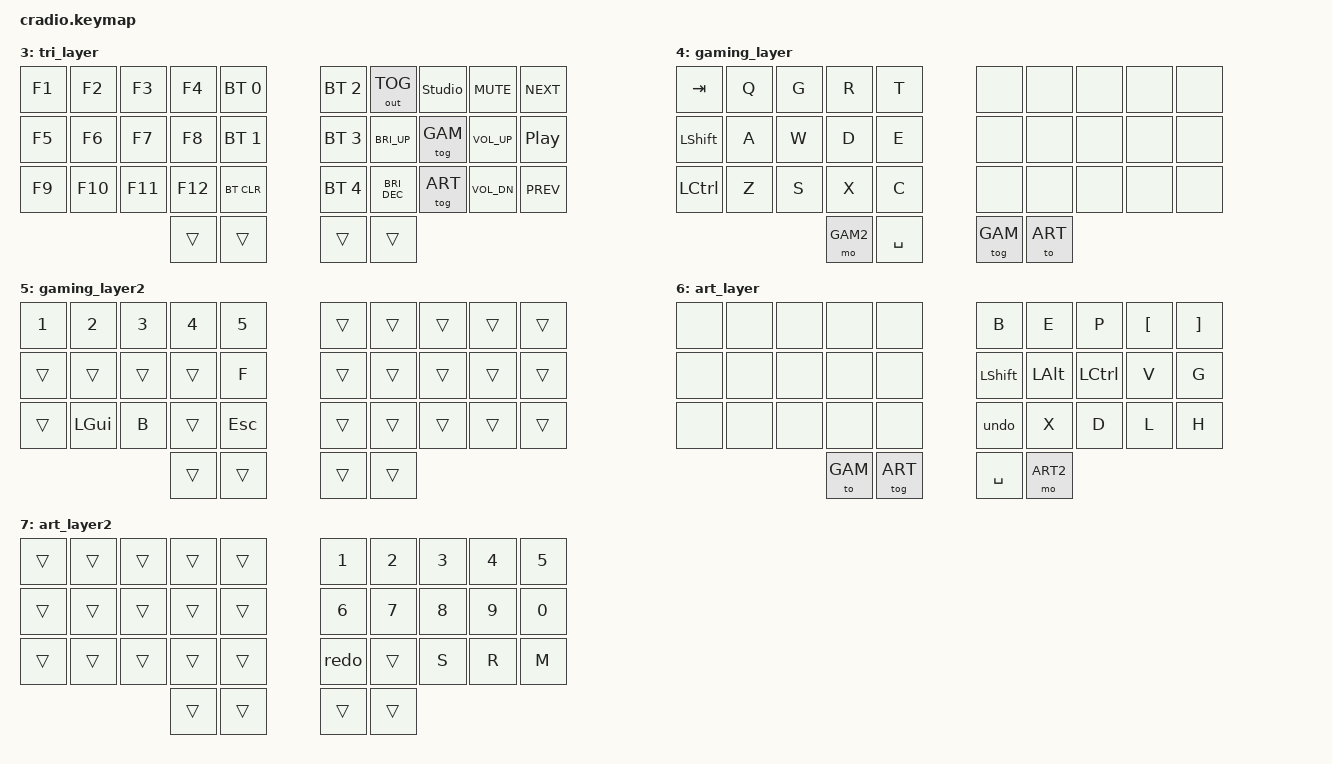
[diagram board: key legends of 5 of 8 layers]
// Copyright (c) 2022 The ZMK Contributors
// SPDX-License-Identifier: MIT

#include <behaviors.dtsi>
#include <dt-bindings/zmk/keys.h>
#include <dt-bindings/zmk/bt.h>
#include <dt-bindings/zmk/outputs.h>

#define DEF 0
#define RIG 1
#define LEF 2
#define TRI 3
#define GAM 4
#define GAM2 5
#define ART 6
#define ART2 7

// Key positions for positional hold-tap
// ╭─────────────────────╮   ╭─────────────────────╮
// │  0   1   2   3   4  │   │  5   6   7   8   9  │
// │ 10  11  12  13  14  │   │ 15  16  17  18  19  │
// │ 20  21  22  23  24  │   │ 25  26  27  28  29  │
// ╰───────────╮ 30  31  │   │ 32  33 ╭────────────╯
//             ╰─────────╯   ╰────────╯
#define KEYS_L 0 1 2 3 4 10 11 12 13 14 20 21 22 23 24
#define KEYS_R 5 6 7 8 9 15 16 17 18 19 25 26 27 28 29
#define THUMBS 30 31 32 33

// Home row mods macros
#define HRML(k1,k2,k3,k4) &hml LALT k1  &hml LCTRL k2  &hml LSHFT k3  &hml LGUI k4
#define HRMR(k1,k2,k3,k4) &hmr LGUI k1  &hmr LSHFT k2  &hmr LCTRL k3  &hmr LALT k4

/ {
    behaviors {
        hml: home_row_mod_left {
            compatible = "zmk,behavior-hold-tap";
            #binding-cells = <2>;
            flavor = "balanced";
            tapping-term-ms = <280>;
            quick-tap-ms = <175>;
            require-prior-idle-ms = <150>;
            bindings = <&kp>, <&kp>;
            hold-trigger-key-positions = <KEYS_R THUMBS>;
            hold-trigger-on-release;
        };

        hmr: home_row_mod_right {
            compatible = "zmk,behavior-hold-tap";
            #binding-cells = <2>;
            flavor = "balanced";
            tapping-term-ms = <280>;
            quick-tap-ms = <175>;
            require-prior-idle-ms = <150>;
            bindings = <&kp>, <&kp>;
            hold-trigger-key-positions = <KEYS_L THUMBS>;
            hold-trigger-on-release;
        };
    };

    macros {
        undo: undo {
            compatible = "zmk,behavior-macro";
            #binding-cells = <0>;
            bindings = <&macro_press &kp LCTRL>, <&macro_tap &kp Z>, <&macro_release &kp LCTRL>;
        };
        redo: redo {
            compatible = "zmk,behavior-macro";
            #binding-cells = <0>;
            bindings = <&macro_press &kp LCTRL &kp LSHFT>, <&macro_tap &kp Z>, <&macro_release &kp LSHFT &kp LCTRL>;
        };

        // Romanian diacritics (AltGr + key, for Romanian Programmers layout)
        ro_a_breve: ro_a_breve {  // Ă
            compatible = "zmk,behavior-macro";
            #binding-cells = <0>;
            bindings = <&macro_press &kp RALT>, <&macro_tap &kp A>, <&macro_release &kp RALT>;
        };
        ro_a_circ: ro_a_circ {  // Â
            compatible = "zmk,behavior-macro";
            #binding-cells = <0>;
            bindings = <&macro_press &kp RALT>, <&macro_tap &kp Q>, <&macro_release &kp RALT>;
        };
        ro_i_circ: ro_i_circ {  // Î
            compatible = "zmk,behavior-macro";
            #binding-cells = <0>;
            bindings = <&macro_press &kp RALT>, <&macro_tap &kp I>, <&macro_release &kp RALT>;
        };
        ro_s_comma: ro_s_comma {  // Ș
            compatible = "zmk,behavior-macro";
            #binding-cells = <0>;
            bindings = <&macro_press &kp RALT>, <&macro_tap &kp S>, <&macro_release &kp RALT>;
        };
        ro_t_comma: ro_t_comma {  // Ț
            compatible = "zmk,behavior-macro";
            #binding-cells = <0>;
            bindings = <&macro_press &kp RALT>, <&macro_tap &kp T>, <&macro_release &kp RALT>;
        };
    };

    conditional_layers {
        compatible = "zmk,conditional-layers";
        tri_layer {
            if-layers = <RIG LEF>;
            then-layer = <TRI>;
        };
    };

    keymap {
        compatible = "zmk,keymap";
        default_layer {
            bindings = <
        //╭──────────┬──────────┬──────────┬──────────┬──────────╮   ╭──────────┬──────────┬──────────┬──────────┬──────────╮
        //│  Q       │  W       │  E       │  R       │  T       │   │  Y       │  U       │  I       │  O       │  P       │
            &kp Q      &kp W      &kp E      &kp R      &kp T          &kp Y      &kp U      &kp I      &kp O      &kp P
        //├──────────┼──────────┼──────────┼──────────┼──────────┤   ├──────────┼──────────┼──────────┼──────────┼──────────┤
        //│  A       │  S/ALT   │  D/CTRL  │  F/SHIFT │  G/GUI   │   │  H/GUI   │  J/SHIFT │  K/CTRL  │  L/ALT   │BACKSPACE │
            &kp A      HRML(S,        D,         F,         G)         HRMR(H,        J,         K,         L)     &kp BSPC
        //├──────────┼──────────┼──────────┼──────────┼──────────┤   ├──────────┼──────────┼──────────┼──────────┼──────────┤
        //│  Z       │  X       │  C       │  V       │  B       │   │  N       │  M       │ , <      │ . >      │ ENTER    │
            &kp Z      &kp X      &kp C      &kp V      &kp B          &kp N      &kp M      &kp COMMA  &kp DOT    &kp ENTER
        //╰──────────┴──────────┴──────────┼──────────┼──────────┤   ├──────────┼──────────┼──────────┴──────────┴──────────╯
                                          &lt LEF TAB  &kp SPACE     &kp SPACE  &lt RIG TAB
        //                                 ╰──────────┴──────────╯   ╰──────────┴──────────╯
            >;
        };

        right_layer {
            bindings = <
        //╭──────────┬──────────┬──────────┬──────────┬──────────╮   ╭──────────┬──────────┬──────────┬──────────┬──────────╮
        //│ 1        │  2       │  3       │  4       │  5       │   │ 6        │ 7        │ 8        │ 9        │   0      │
            &kp N1    &kp N2     &kp N3     &kp N4     &kp N5          &kp N6     &kp N7     &kp N8     &kp N9      &kp N0
        //├──────────┼──────────┼──────────┼──────────┼──────────┤   ├──────────┼──────────┼──────────┼──────────┼──────────┤
        //│  Ă       │  Â       │  Î       │  Ș       │  Ț       |   |HOME/GUI  │PGDN/SHFT │PGUP/CTRL │ END/ALT  │          │
          &ro_a_breve &ro_a_circ &ro_i_circ &ro_s_comma &ro_t_comma  HRMR(HOME,     PG_DN,     PG_UP,     END)      &trans
        //├──────────┼──────────┼──────────┼──────────┼──────────┤   ├──────────┼──────────┼──────────┼──────────┼──────────┤
        //│ DELETE   │ CapsLock │ PrintSc  │  INSERT  │ ESCAPE   │   │ LEFT     │ DOWN     │ UP       │ RIGHT    │          │
            &kp DEL   &kp CAPS   &kp PSCRN  &kp INS    &kp ESC        &kp LARW   &kp DARW   &kp UARW   &kp RARW    &trans
        //╰──────────┴──────────┴──────────┼──────────┼──────────┤   ├──────────┼──────────┼──────────┴──────────┴──────────╯
                                             &trans     &trans         &trans     &trans
        //                                 ╰──────────┴──────────╯   ╰──────────┴──────────╯
            >;
        };

        left_layer {
            bindings = <
        //╭──────────┬──────────┬──────────┬──────────┬──────────╮   ╭──────────┬──────────┬──────────┬──────────┬──────────╮
        //│  !       │  @       │  #       │  $       │  %       │   │  ^       │  &       │  *       │  `       │  ~       │
            &kp EXCL   &kp AT     &kp HASH   &kp DLLR   &kp PRCNT      &kp CARET  &kp AMPS   &kp ASTRK  &kp GRAVE   &kp TILDE
        //├──────────┼──────────┼──────────┼──────────┼──────────┤   ├──────────┼──────────┼──────────┼──────────┼──────────┤
        //│  "       │  [/ALT   │  {/CTRL  │  (/SHIFT │          │   │   //GUI  │  -/SHIFT │  =/CTRL  │  :/ALT   │  ;       │
            &kp DQT  &hml LALT LBKT &hml LCTRL LBRC &hml LSHFT LPAR &trans   HRMR(FSLH,     MINUS,     EQUAL,     COLON)   &kp SEMI
        //├──────────┼──────────┼──────────┼──────────┼──────────┤   ├──────────┼──────────┼──────────┼──────────┼──────────┤
        //│  '       │  ]       │  }       │  )       │          │   │    \     │  _       │  +       │  │       │   ?      │
            &kp SQT     &kp RBKT   &kp RBRC   &kp RPAR   &trans         &kp BSLH   &kp UNDER  &kp PLUS   &kp PIPE  &kp QMARK
        //╰──────────┴──────────┴──────────┼──────────┼──────────┤   ├──────────┼──────────┼──────────┴──────────┴──────────╯
                                             &trans     &trans         &trans     &trans
        //                                 ╰──────────┴──────────╯   ╰──────────┴──────────╯
            >;
        };

        tri_layer {
            bindings = <
        //╭──────────┬──────────┬──────────┬───────────┬────────────╮   ╭────────────┬────────────┬──────────┬───────────┬──────────╮
        //│  F1      │  F2      │  F3      │  F4       │ PROFILE 0  │   │ PROFILE 2  │ TOGGLEOUT  │ STUDIO   │ VOL MUTE  │ NEXTSONG │
            &kp F1     &kp F2     &kp F3     &kp F4     &bt BT_SEL 0     &bt BT_SEL 2  &out OUT_TOG  &studio_unlock  &kp C_MUTE  &kp C_NEXT
        //├──────────┼──────────┼──────────┼───────────┼────────────┤   ├────────────┼────────────┼──────────┼───────────┼──────────┤
        //│  F5      │  F6      │  F7      │  F8       │ PROFILE 1  │   │ PROFILE 3  │ INC BRIGHT │ GAMING   │  VOL UP   │PAUSEMUSIC│
            &kp F5     &kp F6     &kp F7     &kp F8     &bt BT_SEL 1     &bt BT_SEL 3  &kp C_BRI_UP  &tog GAM  &kp C_VOL_UP  &kp C_PP
        //├──────────┼──────────┼──────────┼───────────┼────────────┤   ├────────────┼────────────┼──────────┼───────────┼──────────┤
        //│  F9      │  F10     │  F11     │  F12      │  CLEAR BT  │   │ PROFILE 4  │ DEC BRIGHT │  ART     |  VOL DOWN │ PREVSONG │
            &kp F9     &kp F10    &kp F11    &kp F12     &bt BT_CLR      &bt BT_SEL 4  &kp C_BRI_DEC  &tog ART  &kp C_VOL_DN &kp C_PREV
        //╰──────────┴──────────┴──────────┼───────────┼────────────┤   ├────────────┼────────────┼──────────┴───────────┴──────────╯
                                                &trans     &trans         &trans     &trans
        //                                  ╰───────────┴──────────╯   ╰──────────┴────────────╯
            >;
        };

        gaming_layer {
            bindings = <
        //╭──────────┬──────────┬──────────┬──────────┬──────────╮   ╭──────────┬──────────┬──────────┬──────────┬──────────╮
        //│  TAB     │  Q       │  G       │  R       │  T       │   │          │          │          │          │          │
            &kp TAB    &kp Q      &kp G      &kp R      &kp T          &none      &none      &none      &none      &none
        //├──────────┼──────────┼──────────┼──────────┼──────────┤   ├──────────┼──────────┼──────────┼──────────┼──────────┤
        //│  LSHIFT  │  A       │  W       │  D       │  E       │   │          │          │          │          │          │
            &kp LSHFT  &kp A      &kp W      &kp D      &kp E          &none      &none      &none      &none      &none
        //├──────────┼──────────┼──────────┼──────────┼──────────┤   ├──────────┼──────────┼──────────┼──────────┼──────────┤
        //│  LCTRL   │  Z       │  S       │  X       │  C       │   │          │          │          │          │          │
            &kp LCTRL  &kp Z      &kp S      &kp X      &kp C          &none      &none      &none      &none      &none
        //╰──────────┴──────────┴──────────┼──────────┼──────────┤   ├──────────┼──────────┼──────────┴──────────┴──────────╯
                                            &mo GAM2    &kp SPACE     &tog GAM   &to ART
        //                                 ╰──────────┴──────────╯   ╰──────────┴──────────╯
            >;
        };

        gaming_layer2 {
            bindings = <
        //╭──────────┬──────────┬──────────┬──────────┬──────────╮   ╭──────────┬──────────┬──────────┬──────────┬──────────╮
        //│  1       │  2       │  3       │  4       │  5       │   │          │          │          │          │          │
            &kp N1     &kp N2     &kp N3     &kp N4     &kp N5         &trans     &trans     &trans     &trans     &trans
        //├──────────┼──────────┼──────────┼──────────┼──────────┤   ├──────────┼──────────┼──────────┼──────────┼──────────┤
        //│  ^       │  ^       │  ^       │  ^       │  F       │   │          │          │          │          │          │
            &trans     &trans     &trans     &trans     &kp F          &trans     &trans     &trans     &trans     &trans
        //├──────────┼──────────┼──────────┼──────────┼──────────┤   ├──────────┼──────────┼──────────┼──────────┼──────────┤
        //│  ^       │  GUI     │  B       │  ^       │  ESC     │   │          │          │          │          │          │
            &trans     &kp LGUI   &kp B      &trans     &kp ESC        &trans     &trans     &trans     &trans     &trans
        //╰──────────┴──────────┴──────────┼──────────┼──────────┤   ├──────────┼──────────┼──────────┴──────────┴──────────╯
                                             &trans     &trans         &trans     &trans
        //                                 ╰──────────┴──────────╯   ╰──────────┴──────────╯
            >;
        };

        art_layer {
            bindings = <
        //╭──────────┬──────────┬──────────┬──────────┬──────────╮   ╭──────────┬──────────┬──────────┬──────────┬──────────╮
        //│          │          │          │          │          │   │  B       │  E       │  P       │  [       │  ]       │
            &none      &none      &none      &none      &none          &kp B      &kp E      &kp P      &kp LBKT   &kp RBKT
        //├──────────┼──────────┼──────────┼──────────┼──────────┤   ├──────────┼──────────┼──────────┼──────────┼──────────┤
        //│          │          │          │          │          │   │  LSHIFT  │  LALT    │  LCTRL   │  V       │  G       │
            &none      &none      &none      &none      &none          &kp LSHFT  &kp LALT   &kp LCTRL  &kp V      &kp G
        //├──────────┼──────────┼──────────┼──────────┼──────────┤   ├──────────┼──────────┼──────────┼──────────┼──────────┤
        //│          │          │          │          │          │   │  UNDO    │  X       │  D       │  L       │  H       │
            &none      &none      &none      &none      &none          &undo      &kp X      &kp D      &kp L      &kp H
        //╰──────────┴──────────┴──────────┼──────────┼──────────┤   ├──────────┼──────────┼──────────┴──────────┴──────────╯
                                             &to GAM    &tog ART      &kp SPACE  &mo ART2
        //                                 ╰──────────┴──────────╯   ╰──────────┴──────────╯
            >;
        };

        art_layer2 {
            bindings = <
        //╭──────────┬──────────┬──────────┬──────────┬──────────╮   ╭──────────┬──────────┬──────────┬──────────┬──────────╮
        //│          │          │          │          │          │   │  1       │  2       │  3       │  4       │  5       │
            &trans     &trans     &trans     &trans     &trans         &kp N1     &kp N2     &kp N3     &kp N4     &kp N5
        //├──────────┼──────────┼──────────┼──────────┼──────────┤   ├──────────┼──────────┼──────────┼──────────┼──────────┤
        //│          │          │          │          │          │   │  6       │  7       │  8       │  9       │  0       │
            &trans     &trans     &trans     &trans     &trans         &kp N6     &kp N7     &kp N8     &kp N9     &kp N0
        //├──────────┼──────────┼──────────┼──────────┼──────────┤   ├──────────┼──────────┼──────────┼──────────┼──────────┤
        //│          │          │          │          │          │   │  REDO    │  ^       │  S       │  R       │  M       │
            &trans     &trans     &trans     &trans     &trans         &redo      &trans     &kp S      &kp R      &kp M
        //╰──────────┴──────────┴──────────┼──────────┼──────────┤   ├──────────┼──────────┼──────────┴──────────┴──────────╯
                                             &trans     &trans         &trans     &trans
        //                                 ╰──────────┴──────────╯   ╰──────────┴──────────╯
            >;
        };
    };
};
